# f28002x_analog_subsys_regs register map
Vendor: Texas Instruments
Peripheral module from a debugger description file (folder C2000).
Address unit: 16 bits
Registers are 16-bit, read-write, no defined reset value unless marked. A register's access mark holds for its fields unless they carry their own. Offsets are as the file gives them; lines under a group give offsets from that group; [hi:lo] are bit positions; {n}, {i} and the like mark numbered series; 'fields as' and 'values as' point back to an identical list; <NAME> marks a mode.

## ANALOG_SUBSYS_REGS — ANALOG SUBSYS Registers
0x60 TSNSCTL — Temperature Sensor Control Register
  [0] ENABLE — Temperature Sensor Enable
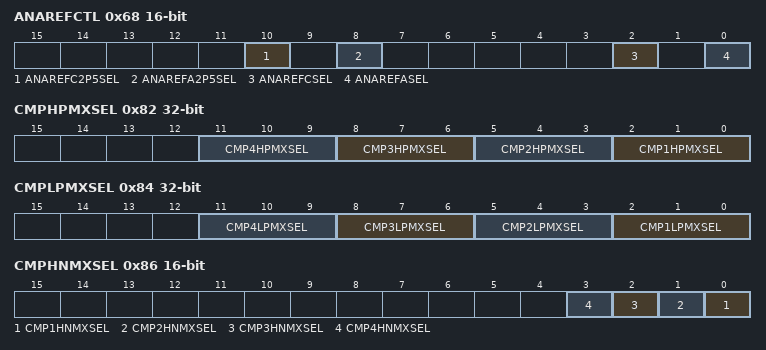
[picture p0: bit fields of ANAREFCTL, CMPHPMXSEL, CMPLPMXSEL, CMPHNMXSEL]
0x68 ANAREFCTL — Analog Reference Control Register
  [10] ANAREFC2P5SEL — Analog Reference C Select
  [8] ANAREFA2P5SEL — Analog Reference A Select
  [2] ANAREFCSEL — Analog Reference C Select
  [0] ANAREFASEL — Analog Reference A Select
0x70 VMONCTL — Voltage Monitor Control Register
  [8] BORLVMONDIS — Disable BORL(ow) feature on VDDIO
0x82 CMPHPMXSEL 32-bit — Bits to select one of the many sources on CopmHP inputs. Refer to Pimux diagram for details.
  [3n-1:3n-3] CMP{n}HPMXSEL (n=1..4) — CMP{n}HPMXSEL bits
0x84 CMPLPMXSEL 32-bit — Bits to select one of the many sources on CopmLP inputs. Refer to Pimux diagram for details.
  [3n-1:3n-3] CMP{n}LPMXSEL (n=1..4) — CMP{n}LPMXSEL bits
0x86 CMPHNMXSEL — Bits to select one of the many sources on CopmHN inputs. Refer to Pimux diagram for details.
  [n-1] CMP{n}HNMXSEL (n=1..4) — CMP{n}HNMXSEL bits
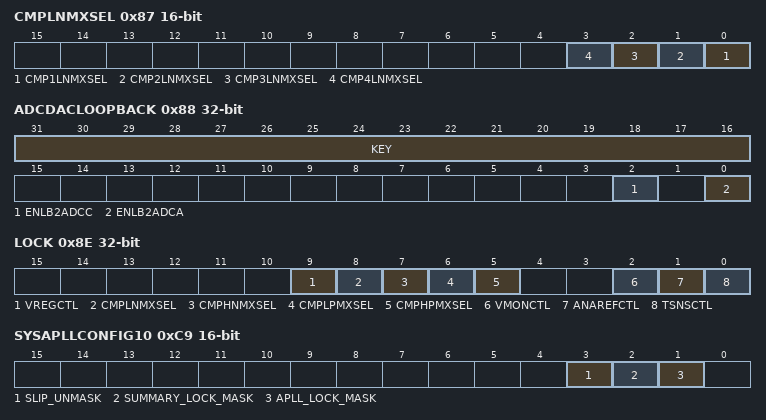
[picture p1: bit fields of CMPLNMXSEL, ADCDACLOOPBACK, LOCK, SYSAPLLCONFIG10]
0x87 CMPLNMXSEL — Bits to select one of the many sources on CopmLN inputs. Refer to Pimux diagram for details.
  [n-1] CMP{n}LNMXSEL (n=1..4) — CMP{n}LNMXSEL bits
0x88 ADCDACLOOPBACK 32-bit — Enabble loopback from DAC to ADCs
  [31:16] KEY — Key to enable writes
  [2] ENLB2ADCC — Enable DACA loopback to ADCC
  [0] ENLB2ADCA — Enable DACA loopback to ADCA
0x8E LOCK 32-bit
  [9] VREGCTL — VREGCTL Register lock bit
  [8] CMPLNMXSEL — CMPLNMXSEL Register lock bit
  [7] CMPHNMXSEL — CMPHNMXSEL Register lock bit
  [6] CMPLPMXSEL — CMPLPMXSEL Register lock bit
  [5] CMPHPMXSEL — CMPHPMXSEL Register lock bit
  [2] VMONCTL — VMONCTL Register lock bit
  [1] ANAREFCTL — ANAREFCTL Register lock bit
  [0] TSNSCTL — TSNSCTL Register lock bit
0xC9 SYSAPLLCONFIG10 — APLL Module (SYSPLL Instance) CONFIG10 Register
  [3] SLIP_UNMASK — SLIP_UNMASK Value
  [2] SUMMARY_LOCK_MASK — SUMMARY_LOCK_MASK Value
  [1] APLL_LOCK_MASK — APLL_LOCK_MASK Value
